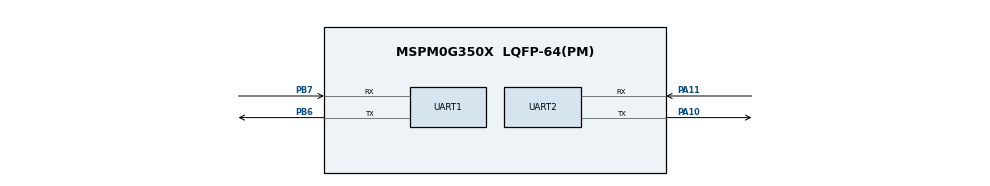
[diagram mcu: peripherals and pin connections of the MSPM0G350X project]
/**
 * @cliArgs --device "MSPM0G350X" --package "LQFP-64(PM)" --part "Default" --product "mspm0_sdk@2.00.01.00"
 * @versions {"tool":"1.20.0+3587"}
 */

/**
 * Import the modules used in this configuration.
 */
const ADC12         = scripting.addModule("/ti/driverlib/ADC12", {}, false);
const ADC121        = ADC12.addInstance();
const SYSCTL        = scripting.addModule("/ti/driverlib/SYSCTL");
const TIMER         = scripting.addModule("/ti/driverlib/TIMER", {}, false);
const TIMER1        = TIMER.addInstance();
const UART          = scripting.addModule("/ti/driverlib/UART", {}, false);
const UART1         = UART.addInstance();
const UART2         = UART.addInstance();
const ProjectConfig = scripting.addModule("/ti/project_config/ProjectConfig");

/**
 * Write custom configuration values to the imported modules.
 */
const divider6       = system.clockTree["PLL_CLK2X_DIV"];
divider6.divideValue = 4;

const divider7       = system.clockTree["PLL_PDIV"];
divider7.divideValue = 2;

const divider9       = system.clockTree["UDIV"];
divider9.divideValue = 2;

const multiplier2         = system.clockTree["PLL_QDIV"];
multiplier2.multiplyValue = 10;

const mux8       = system.clockTree["HSCLKMUX"];
mux8.inputSelect = "HSCLKMUX_SYSPLL2X";

ADC121.$name                             = "ADC12_0";
ADC121.repeatMode                        = true;
ADC121.trigSrc                           = "DL_ADC12_TRIG_SRC_EVENT";
ADC121.sampleTime0                       = "62.5 ns";
ADC121.enabledInterrupts                 = ["DL_ADC12_INTERRUPT_DMA_DONE"];
ADC121.configureDMA                      = true;
ADC121.sampCnt                           = 1;
ADC121.subChanID                         = 1;
ADC121.enabledDMATriggers                = ["DL_ADC12_DMA_MEM0_RESULT_LOADED"];
ADC121.powerDownMode                     = "DL_ADC12_POWER_DOWN_MODE_MANUAL";
ADC121.adcMem0trig                       = "DL_ADC12_TRIGGER_MODE_TRIGGER_NEXT";
ADC121.peripheral.$assign                = "ADC0";
ADC121.peripheral.adcPin0.$assign        = "PA27";
ADC121.adcPin0Config.$name               = "ti_driverlib_gpio_GPIOPinGeneric2";
ADC121.DMA_CHANNEL.$name                 = "DMA_CH0";
ADC121.DMA_CHANNEL.addressMode           = "f2b";
ADC121.DMA_CHANNEL.srcLength             = "HALF_WORD";
ADC121.DMA_CHANNEL.dstLength             = "HALF_WORD";
ADC121.DMA_CHANNEL.configureTransferSize = true;
ADC121.DMA_CHANNEL.transferSize          = 1024;
ADC121.DMA_CHANNEL.transferMode          = "FULL_CH_REPEAT_SINGLE";

const Board = scripting.addModule("/ti/driverlib/Board", {}, false);

SYSCTL.forceDefaultClkConfig = true;
SYSCTL.clockTreeEn           = true;

TIMER1.$name                       = "TIMER_0";
TIMER1.timerPeriod                 = "1 us";
TIMER1.timerMode                   = "PERIODIC";
TIMER1.event1PublisherChannel      = 1;
TIMER1.event1ControllerInterruptEn = ["ZERO_EVENT"];
TIMER1.peripheral.$assign          = "TIMG6";

UART1.$name                            = "UART_BIUTEETH";
UART1.peripheral.rxPin.$assign         = "PB7";
UART1.peripheral.txPin.$assign         = "PB6";
UART1.txPinConfig.direction            = scripting.forceWrite("OUTPUT");
UART1.txPinConfig.hideOutputInversion  = scripting.forceWrite(false);
UART1.txPinConfig.onlyInternalResistor = scripting.forceWrite(false);
UART1.txPinConfig.passedPeripheralType = scripting.forceWrite("Digital");
UART1.txPinConfig.$name                = "ti_driverlib_gpio_GPIOPinGeneric3";
UART1.rxPinConfig.hideOutputInversion  = scripting.forceWrite(false);
UART1.rxPinConfig.onlyInternalResistor = scripting.forceWrite(false);
UART1.rxPinConfig.passedPeripheralType = scripting.forceWrite("Digital");
UART1.rxPinConfig.$name                = "ti_driverlib_gpio_GPIOPinGeneric4";

UART2.$name                    = "UART_0";
UART2.targetBaudRate           = 115200;
UART2.peripheral.$assign       = "UART0";
UART2.peripheral.rxPin.$assign = "PA11";
UART2.peripheral.txPin.$assign = "PA10";
UART2.txPinConfig.$name        = "ti_driverlib_gpio_GPIOPinGeneric0";
UART2.rxPinConfig.$name        = "ti_driverlib_gpio_GPIOPinGeneric1";

ProjectConfig.genLibCMSIS = true;

/**
 * Pinmux solution for unlocked pins/peripherals. This ensures that minor changes to the automatic solver in a future
 * version of the tool will not impact the pinmux you originally saw.  These lines can be completely deleted in order to
 * re-solve from scratch.
 */
ADC121.DMA_CHANNEL.peripheral.$suggestSolution = "DMA_CH0";
Board.peripheral.$suggestSolution              = "DEBUGSS";
Board.peripheral.swclkPin.$suggestSolution     = "PA20";
Board.peripheral.swdioPin.$suggestSolution     = "PA19";
UART1.peripheral.$suggestSolution              = "UART1";
